# STM32G474 register map
File version: 2.9
CPU: CM4 r0p1, little endian, MPU, FPU, 4 interrupt priority bits
Registers are 32-bit, read-write, reset 0x0 unless marked. A register's access mark holds for its fields unless they carry their own. Offsets are from the block's base; [hi:lo] are bit positions; {n}, {i} and the like mark numbered series; 'fields as' and 'values as' point back to an identical list.

## HRTIM_Master — High Resolution Timer: Master Timers
Base 0x40016800
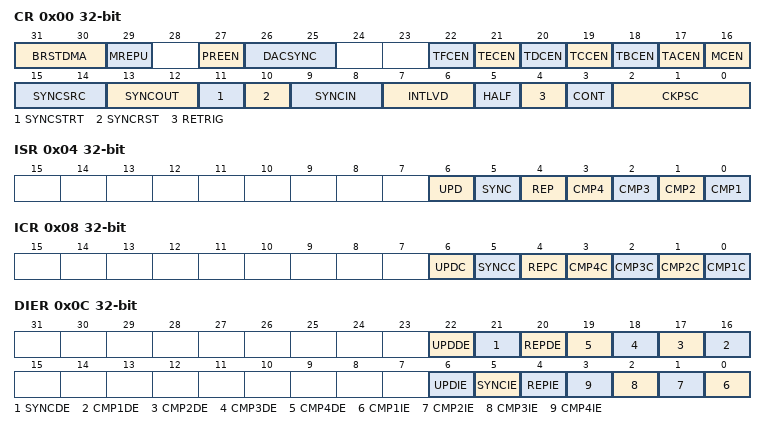
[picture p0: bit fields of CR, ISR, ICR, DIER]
0x00 CR — Master Timer Control Register
  [31:30] BRSTDMA — Burst DMA Update
    0=Independent (Update done independently from the DMA burst transfer completion); 1=Completion (Update done when the DMA burst transfer is completed); 2=Rollover (Update done on master timer roll-over following a DMA burst transfer completion)
  [29] MREPU — Master Timer Repetition update
    0=Disabled (Update on repetition disabled); 1=Enabled (Update on repetition enabled)
  [27] PREEN — Preload enable
    0=Disabled (Preload disabled: the write access is directly done into the active register); 1=Enabled (Preload enabled: the write access is done into the preload register)
  [26:25] DACSYNC — AC Synchronization
    0=Disabled (No DAC trigger generated); 1=Trigger generated on DACSync1; 2=Trigger generated on DACSync2; 3=Trigger generated on DACSync3
  [17] T{x}CEN (x=A,B,C,D,E,F; step 1) — Timer {x} counter enable
    0=Disabled (Timer counter disabled); 1=Enabled (Timer counter enabled)
  [16] MCEN — Master Counter enable
    0=Disabled (Master timer counter disabled); 1=Enabled (Master timer counter enabled)
  [15:14] SYNCSRC — Synchronization source
    0=MasterStart (Master timer Start); 1=MasterCompare1 (Master timer Compare 1 event); 2=Timer A start/reset; 3=Timer A Compare 1 event
  [13:12] SYNCOUT — Synchronization output
    0=Disabled; 2=Positive pulse on SCOUT output (16x f_HRTIM clock cycles); 3=Negative pulse on SCOUT output (16x f_HRTIM clock cycles)
  [11] SYNCSTRT — Synchronization Starts Master
    0=Disabled (No effect on the master timer); 1=Start (A synchroniation input event starts the master timer)
  [10] SYNCRST — Synchronization Resets Master
    0=Disabled (No effect on the master timer); 1=Reset (A synchroniation input event resets the master timer)
  [9:8] SYNCIN — synchronization input
    0=Disabled. HRTIM is not synchronized and runs in standalone mode; 2=Internal event: the HRTIM is synchronized with the on-chip timer; 3=External event: a positive pulse on HRTIM_SCIN input triggers the HRTIM
  [7:6] INTLVD — Interleaved mode
  [5] HALF — Half mode enable
    0=Disabled (Half mode disabled); 1=Enabled (Half mode enabled)
  [4] RETRIG — Master Re-triggerable mode
    0=Disabled (The timer is not re-triggerable: a counter reset can be done only if the counter is stopped); 1=Enabled (The timer is retriggerable: a counter reset is done whatever the counter state)
  [3] CONT — Master Continuous mode
    0=SingleShot (The timer operates in single-shot mode and stops when it reaches the MPER value); 1=Continuous (The timer operates in continuous (free-running) mode and rolls over to zero when it reaches the MPER value)
  [2:0] CKPSC — HRTIM Master Clock prescaler
0x04 ISR ro — Master Timer Interrupt Status Register
  [6] UPD — Master Update Interrupt Flag
    0=NoEvent (No timer update interrupt occurred); 1=Event (Timer update interrupt occurred)
  [5] SYNC — Sync Input Interrupt Flag
    0=NoEvent (No sync input interrupt occurred); 1=Event (Sync input interrupt occurred)
  [4] REP — Master Repetition Interrupt Flag
    0=NoEvent (No timer repetition interrupt occurred); 1=Event (Timer repetition interrupt occurred)
  [n-1] CMP{n} (n=1..4) — Master Compare {n} Interrupt Flag
    0=NoEvent (No compare interrupt occurred); 1=Event (Compare interrupt occurred)
0x08 ICR wo — Master Timer Interrupt Clear Register
  [all] fields
    1=Clears associated flag in ISR register
  [6] UPDC write-1-clears — Master update Interrupt flag clear
  [5] SYNCC write-1-clears — Sync Input Interrupt flag clear
  [4] REPC write-1-clears — Repetition Interrupt flag clear
  [n-1] CMP{n}C (n=1..4) write-1-clears — Master Compare {n} Interrupt flag clear
0x0C DIER — HRTIM Master Timer DMA / Interrupt Enable Register
  [22] UPDDE — MUPDDE
    0=Disabled (DMA request disabled); 1=Enabled (DMA request enabled)
  [21] SYNCDE
    values as UPDDE
  [20] REPDE — MREPDE
    values as UPDDE
  [n+15] CMP{n}DE (n=1..4) — MCMP{n}DE
    values as UPDDE
  [6] UPDIE — MUPDIE
    0=Disabled (Interrupt disabled); 1=Enabled (Interrupt enabled)
  [5] SYNCIE
    values as UPDIE
  [4] REPIE — MREPIE
    values as UPDIE
  [n-1] CMP{n}IE (n=1..4) — MCMP{n}IE
    values as UPDIE
0x10 CNTR — Master Timer Counter Register
  [15:0] CNT — Counter value
0x14 PERR reset 0xFFFF — Master Timer Period Register
  [15:0] PER — Master Timer Period value
0x18 REPR — Master Timer Repetition Register
  [7:0] REP — Master Timer Repetition counter value
0x1C CMP1R — Master Timer Compare 1 Register
  [15:0] CMP — Master Timer Compare 1 value
{0x1C+4i} CMP{i}R (i=2..4) — Master Timer Compare {i} Register
  [15:0] CMP — Master Timer Compare 1 value
